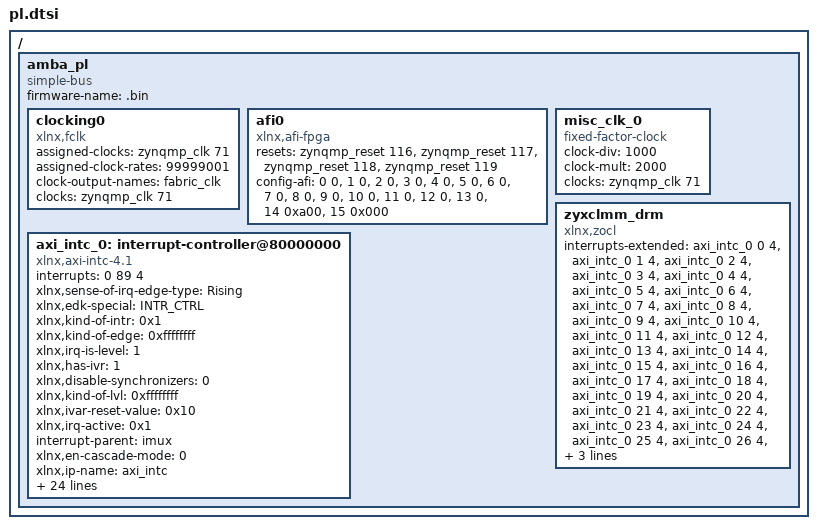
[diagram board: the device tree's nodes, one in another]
/ {
	amba_pl: amba_pl {
		ranges;
		compatible = "simple-bus";
		#address-cells = <2>;
		#size-cells = <2>;
		firmware-name = ".bin";
		clocking0: clocking0 {
			compatible = "xlnx,fclk";
			status = "okay";
			assigned-clocks = <&zynqmp_clk 71>;
			assigned-clock-rates = <99999001>;
			#clock-cells = <0>;
			clock-output-names = "fabric_clk";
			clocks = <&zynqmp_clk 71>;
		};
		afi0: afi0 {
			status = "okay";
			compatible = "xlnx,afi-fpga";
			resets = <&zynqmp_reset 116>, <&zynqmp_reset 117>, <&zynqmp_reset 118>, <&zynqmp_reset 119>;
			config-afi = < 0 0>, <1 0>, <2 0>, <3 0>, <4 0>, <5 0>, <6 0>, <7 0>, <8 0>, <9 0>, <10 0>, <11 0>, <12 0>, <13 0>, <14 0xa00>, <15 0x000>;
		};
		misc_clk_0: misc_clk_0 {
			clock-div = <1000>;
			compatible = "fixed-factor-clock";
			clock-mult = <2000>;
			clocks = <&zynqmp_clk 71>;
			#clock-cells = <0>;
		};
		axi_intc_0: interrupt-controller@80000000 {
			#interrupt-cells = <2>;
			interrupts = < 0 89 4 >;
			xlnx,sense-of-irq-edge-type = "Rising";
			xlnx,edk-special = "INTR_CTRL";
			xlnx,kind-of-intr = <0x1>;
			xlnx,kind-of-edge = <0xffffffff>;
			xlnx,irq-is-level = <1>;
			xlnx,has-ivr = <1>;
			compatible = "xlnx,axi-intc-4.1" , "xlnx,xps-intc-1.00.a";
			xlnx,disable-synchronizers = <0>;
			xlnx,kind-of-lvl = <0xffffffff>;
			xlnx,ivar-reset-value = <0x10>;
			xlnx,irq-active = <0x1>;
			interrupt-parent = <&imux>;
			xlnx,en-cascade-mode = <0>;
			xlnx,ip-name = "axi_intc";
			xlnx,has-ilr = <0>;
			reg = <0x0 0x80000000 0x0 0x10000>;
			xlnx,addr-width = <0x20>;
			clocks = <&misc_clk_0>;
			xlnx,s-axi-aclk-freq-mhz = <0xbebba30>;
			xlnx,num-sw-intr = <0>;
			xlnx,irq-connection = <1>;
			xlnx,num-intr-inputs = <0x20>;
			xlnx,has-sie = <1>;
			xlnx,enable-async = <0>;
			xlnx,has-cie = <1>;
			xlnx,num-sync-ff = <2>;
			xlnx,edk-iptype = "PERIPHERAL";
			xlnx,mb-clk-not-connected = <1>;
			xlnx,has-ipr = <1>;
			xlnx,sense-of-irq-level-type = "Active_High";
			xlnx,cascade-master = <0>;
			xlnx,processor-clk-freq-mhz = <100>;
			status = "okay";
			xlnx,is-fast = <0x0>;
			clock-names = "s_axi_aclk";
			xlnx,has-fast = <0>;
			xlnx,ivar-rst-val = <0x10>;
			interrupt-controller;
			interrupt-names = "irq";
			xlnx,async-intr = <0xffffffff>;
			xlnx,name = "axi_intc_0";
		};
		zyxclmm_drm {
			compatible = "xlnx,zocl";
			interrupts-extended = <&axi_intc_0 0 4>, <&axi_intc_0 1 4>, <&axi_intc_0 2 4>, <&axi_intc_0 3 4>, <&axi_intc_0 4 4>, <&axi_intc_0 5 4>, <&axi_intc_0 6 4>, <&axi_intc_0 7 4>, <&axi_intc_0 8 4>, <&axi_intc_0 9 4>, <&axi_intc_0 10 4>, <&axi_intc_0 11 4>, <&axi_intc_0 12 4>, <&axi_intc_0 13 4>, <&axi_intc_0 14 4>, <&axi_intc_0 15 4>, <&axi_intc_0 16 4>, <&axi_intc_0 17 4>, <&axi_intc_0 18 4>, <&axi_intc_0 19 4>, <&axi_intc_0 20 4>, <&axi_intc_0 21 4>, <&axi_intc_0 22 4>, <&axi_intc_0 23 4>, <&axi_intc_0 24 4>, <&axi_intc_0 25 4>, <&axi_intc_0 26 4>, <&axi_intc_0 27 4>, <&axi_intc_0 28 4>, <&axi_intc_0 29 4>, <&axi_intc_0 30 4>, <&axi_intc_0 31 4>;
		};
	};
};
